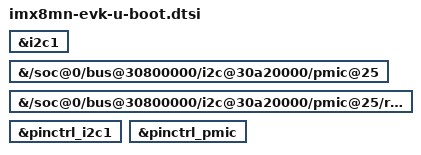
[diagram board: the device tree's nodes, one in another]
// SPDX-License-Identifier: GPL-2.0+
/*
 * Copyright 2019 NXP
 */

#include "imx8mn-ddr4-evk-u-boot.dtsi"

&i2c1 {
	u-boot,dm-spl;
};

&{/soc@0/bus@30800000/i2c@30a20000/pmic@25} {
	u-boot,dm-spl;
};

&{/soc@0/bus@30800000/i2c@30a20000/pmic@25/regulators} {
	u-boot,dm-spl;
};

&pinctrl_i2c1 {
	u-boot,dm-spl;
};

&pinctrl_pmic {
	u-boot,dm-spl;
};
